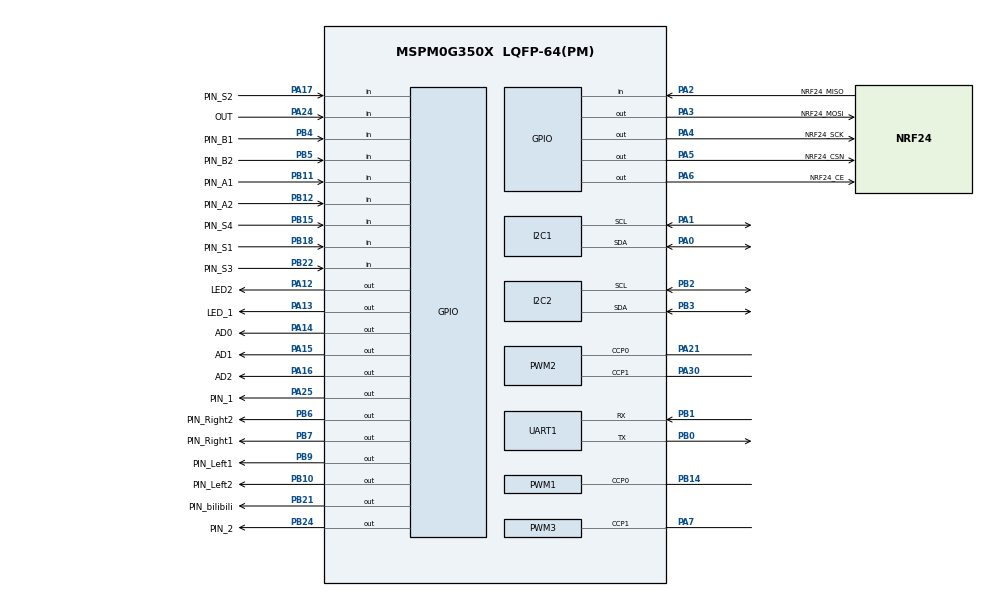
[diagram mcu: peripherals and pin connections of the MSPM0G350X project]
/**
 *
 * @cliArgs --device "MSPM0G350X" --part "Default" --package "LQFP-64(PM)" --product "mspm0_sdk@2.11.00.07"
 * @versions {"tool":"1.28.0+4696"}
 */

/**
 * Import the modules used in this configuration.
 */
const GPIO   = scripting.addModule("/ti/driverlib/GPIO", {}, false);
const GPIO1  = GPIO.addInstance();
const GPIO2  = GPIO.addInstance();
const GPIO3  = GPIO.addInstance();
const GPIO4  = GPIO.addInstance();
const GPIO5  = GPIO.addInstance();
const GPIO6  = GPIO.addInstance();
const GPIO7  = GPIO.addInstance();
const GPIO8  = GPIO.addInstance();
const I2C    = scripting.addModule("/ti/driverlib/I2C", {}, false);
const I2C1   = I2C.addInstance();
const I2C2   = I2C.addInstance();
const PWM    = scripting.addModule("/ti/driverlib/PWM", {}, false);
const PWM1   = PWM.addInstance();
const PWM2   = PWM.addInstance();
const PWM3   = PWM.addInstance();
const SYSCTL = scripting.addModule("/ti/driverlib/SYSCTL");
const TIMER  = scripting.addModule("/ti/driverlib/TIMER", {}, false);
const TIMER1 = TIMER.addInstance();
const TIMER2 = TIMER.addInstance();
const UART   = scripting.addModule("/ti/driverlib/UART", {}, false);
const UART1  = UART.addInstance();

/**
 * Write custom configuration values to the imported modules.
 */
GPIO1.$name                              = "GPIO_Key";
GPIO1.associatedPins.create(4);
GPIO1.associatedPins[0].$name            = "PIN_S1";
GPIO1.associatedPins[0].direction        = "INPUT";
GPIO1.associatedPins[0].internalResistor = "PULL_UP";
GPIO1.associatedPins[0].pin.$assign      = "PB18";
GPIO1.associatedPins[1].$name            = "PIN_S2";
GPIO1.associatedPins[1].direction        = "INPUT";
GPIO1.associatedPins[1].internalResistor = "PULL_UP";
GPIO1.associatedPins[1].pin.$assign      = "PA17";
GPIO1.associatedPins[2].$name            = "PIN_S3";
GPIO1.associatedPins[2].direction        = "INPUT";
GPIO1.associatedPins[2].internalResistor = "PULL_UP";
GPIO1.associatedPins[2].pin.$assign      = "PB22";
GPIO1.associatedPins[3].$name            = "PIN_S4";
GPIO1.associatedPins[3].internalResistor = "PULL_UP";
GPIO1.associatedPins[3].direction        = "INPUT";
GPIO1.associatedPins[3].pin.$assign      = "PB15";

const Board = scripting.addModule("/ti/driverlib/Board", {}, false);

GPIO2.$name                         = "GPIO_Motor";
GPIO2.associatedPins.create(4);
GPIO2.associatedPins[0].$name       = "PIN_Left1";
GPIO2.associatedPins[0].pin.$assign = "PB9";
GPIO2.associatedPins[1].$name       = "PIN_Left2";
GPIO2.associatedPins[1].pin.$assign = "PB10";
GPIO2.associatedPins[2].$name       = "PIN_Right1";
GPIO2.associatedPins[2].pin.$assign = "PB7";
GPIO2.associatedPins[3].$name       = "PIN_Right2";
GPIO2.associatedPins[3].pin.$assign = "PB6";

GPIO3.$name                               = "GPIO_ENCODER";
GPIO3.associatedPins.create(4);
GPIO3.associatedPins[0].direction         = "INPUT";
GPIO3.associatedPins[0].interruptEn       = true;
GPIO3.associatedPins[0].$name             = "PIN_A1";
GPIO3.associatedPins[0].interruptPriority = "0";
GPIO3.associatedPins[0].polarity          = "RISE";
GPIO3.associatedPins[0].pin.$assign       = "PB11";
GPIO3.associatedPins[1].direction         = "INPUT";
GPIO3.associatedPins[1].$name             = "PIN_B1";
GPIO3.associatedPins[1].polarity          = "RISE";
GPIO3.associatedPins[1].interruptEn       = true;
GPIO3.associatedPins[1].interruptPriority = "0";
GPIO3.associatedPins[1].pin.$assign       = "PB4";
GPIO3.associatedPins[2].direction         = "INPUT";
GPIO3.associatedPins[2].interruptEn       = true;
GPIO3.associatedPins[2].$name             = "PIN_A2";
GPIO3.associatedPins[2].interruptPriority = "0";
GPIO3.associatedPins[2].polarity          = "RISE";
GPIO3.associatedPins[2].pin.$assign       = "PB12";
GPIO3.associatedPins[3].direction         = "INPUT";
GPIO3.associatedPins[3].$name             = "PIN_B2";
GPIO3.associatedPins[3].interruptEn       = true;
GPIO3.associatedPins[3].polarity          = "RISE";
GPIO3.associatedPins[3].interruptPriority = "0";
GPIO3.associatedPins[3].pin.$assign       = "PB5";

GPIO4.$name                              = "GPIO_Follow";
GPIO4.associatedPins.create(4);
GPIO4.associatedPins[0].direction        = "INPUT";
GPIO4.associatedPins[0].internalResistor = "PULL_DOWN";
GPIO4.associatedPins[0].$name            = "OUT";
GPIO4.associatedPins[0].pin.$assign      = "PA24";
GPIO4.associatedPins[1].internalResistor = "PULL_DOWN";
GPIO4.associatedPins[1].$name            = "AD0";
GPIO4.associatedPins[1].pin.$assign      = "PA14";
GPIO4.associatedPins[2].internalResistor = "PULL_DOWN";
GPIO4.associatedPins[2].$name            = "AD1";
GPIO4.associatedPins[2].pin.$assign      = "PA15";
GPIO4.associatedPins[3].internalResistor = "PULL_DOWN";
GPIO4.associatedPins[3].$name            = "AD2";
GPIO4.associatedPins[3].pin.$assign      = "PA16";

GPIO5.$name                          = "GPIO_Buzzer";
GPIO5.associatedPins[0].$name        = "PIN_bilibili";
GPIO5.associatedPins[0].initialValue = "SET";
GPIO5.associatedPins[0].pin.$assign  = "PB21";

GPIO6.$name                         = "GPIO_LED";
GPIO6.associatedPins.create(2);
GPIO6.associatedPins[0].$name       = "LED_1";
GPIO6.associatedPins[0].pin.$assign = "PA13";
GPIO6.associatedPins[1].$name       = "LED2";
GPIO6.associatedPins[1].pin.$assign = "PA12";

GPIO7.$name                          = "GPIO_Magnet";
GPIO7.associatedPins.create(3);
GPIO7.associatedPins[0].$name        = "PIN_0";
GPIO7.associatedPins[0].initialValue = "SET";
GPIO7.associatedPins[1].$name        = "PIN_1";
GPIO7.associatedPins[1].initialValue = "SET";
GPIO7.associatedPins[1].pin.$assign  = "PA25";
GPIO7.associatedPins[2].$name        = "PIN_2";
GPIO7.associatedPins[2].initialValue = "SET";
GPIO7.associatedPins[2].pin.$assign  = "PB24";

GPIO8.$name                          = "GPIO_NRF";
GPIO8.associatedPins.create(5);
GPIO8.associatedPins[0].$name        = "NRF24_CE";
GPIO8.associatedPins[0].assignedPort = "PORTA";
GPIO8.associatedPins[0].assignedPin  = "6";
GPIO8.associatedPins[0].pin.$assign  = "PA6";
GPIO8.associatedPins[1].$name        = "NRF24_CSN";
GPIO8.associatedPins[1].initialValue = "SET";
GPIO8.associatedPins[1].assignedPort = "PORTA";
GPIO8.associatedPins[1].assignedPin  = "5";
GPIO8.associatedPins[1].pin.$assign  = "PA5";
GPIO8.associatedPins[2].$name        = "NRF24_SCK";
GPIO8.associatedPins[2].pin.$assign  = "PA4";
GPIO8.associatedPins[3].$name        = "NRF24_MOSI";
GPIO8.associatedPins[3].pin.$assign  = "PA3";
GPIO8.associatedPins[4].$name        = "NRF24_MISO";
GPIO8.associatedPins[4].direction    = "INPUT";
GPIO8.associatedPins[4].pin.$assign  = "PA2";

I2C1.$name                             = "I2C_OLED";
I2C1.basicEnableController             = true;
I2C1.intController                     = ["ARBITRATION_LOST","NACK","RXFIFO_TRIGGER","RX_DONE","TX_DONE"];
I2C1.basicControllerStandardBusSpeed   = "Fast";
I2C1.peripheral.sdaPin.$assign         = "PA0";
I2C1.peripheral.sclPin.$assign         = "PA1";
I2C1.sdaPinConfig.$name                = "ti_driverlib_gpio_GPIOPinGeneric0";
I2C1.sdaPinConfig.hideOutputInversion  = scripting.forceWrite(false);
I2C1.sdaPinConfig.onlyInternalResistor = scripting.forceWrite(false);
I2C1.sdaPinConfig.passedPeripheralType = scripting.forceWrite("Digital");
I2C1.sclPinConfig.$name                = "ti_driverlib_gpio_GPIOPinGeneric1";
I2C1.sclPinConfig.hideOutputInversion  = scripting.forceWrite(false);
I2C1.sclPinConfig.onlyInternalResistor = scripting.forceWrite(false);
I2C1.sclPinConfig.passedPeripheralType = scripting.forceWrite("Digital");

I2C2.$name                             = "I2C_MPU6050";
I2C2.basicEnableController             = true;
I2C2.intController                     = ["ARBITRATION_LOST","NACK","RXFIFO_TRIGGER","RX_DONE","TX_DONE"];
I2C2.peripheral.sdaPin.$assign         = "PB3";
I2C2.peripheral.sclPin.$assign         = "PB2";
I2C2.sdaPinConfig.$name                = "ti_driverlib_gpio_GPIOPinGeneric2";
I2C2.sdaPinConfig.hideOutputInversion  = scripting.forceWrite(false);
I2C2.sdaPinConfig.onlyInternalResistor = scripting.forceWrite(false);
I2C2.sdaPinConfig.passedPeripheralType = scripting.forceWrite("Digital");
I2C2.sclPinConfig.$name                = "ti_driverlib_gpio_GPIOPinGeneric3";
I2C2.sclPinConfig.hideOutputInversion  = scripting.forceWrite(false);
I2C2.sclPinConfig.onlyInternalResistor = scripting.forceWrite(false);
I2C2.sclPinConfig.passedPeripheralType = scripting.forceWrite("Digital");

PWM1.$name                              = "PWM_Car";
PWM1.pwmMode                            = "EDGE_ALIGN_UP";
PWM1.timerCount                         = 3200;
PWM1.timerStartTimer                    = true;
PWM1.ccIndex                            = [0];
PWM1.PWM_CHANNEL_0.$name                = "ti_driverlib_pwm_PWMTimerCC0";
PWM1.ccp0PinConfig.$name                = "ti_driverlib_gpio_GPIOPinGeneric4";
PWM1.ccp0PinConfig.direction            = scripting.forceWrite("OUTPUT");
PWM1.ccp0PinConfig.hideOutputInversion  = scripting.forceWrite(false);
PWM1.ccp0PinConfig.onlyInternalResistor = scripting.forceWrite(false);
PWM1.ccp0PinConfig.passedPeripheralType = scripting.forceWrite("Digital");
PWM1.peripheral.$assign                 = "TIMA0";
PWM1.peripheral.ccp0Pin.$assign         = "PB14";

PWM2.$name                              = "PWM_Servo";
PWM2.enableShadowLoad                   = true;
PWM2.dutyArgs                           = "[2.5,2.5,0,0]";
PWM2.clockDivider                       = 8;
PWM2.clockPrescale                      = 80;
PWM2.peripheral.$assign                 = "TIMG6";
PWM2.peripheral.ccp0Pin.$assign         = "PA21";
PWM2.peripheral.ccp1Pin.$assign         = "PA30";
PWM2.PWM_CHANNEL_0.$name                = "ti_driverlib_pwm_PWMTimerServo0";
PWM2.PWM_CHANNEL_1.$name                = "ti_driverlib_pwm_PWMTimerServo1";
PWM2.ccp0PinConfig.direction            = scripting.forceWrite("OUTPUT");
PWM2.ccp0PinConfig.hideOutputInversion  = scripting.forceWrite(false);
PWM2.ccp0PinConfig.onlyInternalResistor = scripting.forceWrite(false);
PWM2.ccp0PinConfig.passedPeripheralType = scripting.forceWrite("Digital");
PWM2.ccp0PinConfig.$name                = "ti_driverlib_gpio_GPIOPinGeneric12";
PWM2.ccp1PinConfig.direction            = scripting.forceWrite("OUTPUT");
PWM2.ccp1PinConfig.hideOutputInversion  = scripting.forceWrite(false);
PWM2.ccp1PinConfig.onlyInternalResistor = scripting.forceWrite(false);
PWM2.ccp1PinConfig.passedPeripheralType = scripting.forceWrite("Digital");
PWM2.ccp1PinConfig.$name                = "ti_driverlib_gpio_GPIOPinGeneric13";

PWM3.$name                              = "PWM_Car_Left";
PWM3.timerCount                         = 3200;
PWM3.timerStartTimer                    = true;
PWM3.ccIndex                            = [1];
PWM3.ccp1PinConfig.direction            = scripting.forceWrite("OUTPUT");
PWM3.ccp1PinConfig.hideOutputInversion  = scripting.forceWrite(false);
PWM3.ccp1PinConfig.onlyInternalResistor = scripting.forceWrite(false);
PWM3.ccp1PinConfig.passedPeripheralType = scripting.forceWrite("Digital");
PWM3.ccp1PinConfig.$name                = "ti_driverlib_gpio_GPIOPinGeneric8";
PWM3.peripheral.$assign                 = "TIMG7";
PWM3.peripheral.ccp1Pin.$assign         = "PA7";
PWM3.PWM_CHANNEL_1.$name                = "ti_driverlib_pwm_PWMTimerCC1";

SYSCTL.forceDefaultClkConfig = true;

TIMER1.$name              = "TIMER_10ms";
TIMER1.timerClkPrescale   = 256;
TIMER1.interrupts         = ["ZERO"];
TIMER1.timerMode          = "PERIODIC";
TIMER1.timerPeriod        = "10ms";
TIMER1.peripheral.$assign = "TIMG0";

TIMER2.$name              = "TIMER_TICK";
TIMER2.timerClkDiv        = 8;
TIMER2.timerClkPrescale   = 10;
TIMER2.timerPeriod        = "20 ms";
TIMER2.interrupts         = ["ZERO"];
TIMER2.interruptPriority  = "3";
TIMER2.peripheral.$assign = "TIMA1";

UART1.uartClkDiv                       = "8";
UART1.rxFifoThreshold                  = "DL_UART_RX_FIFO_LEVEL_ONE_ENTRY";
UART1.enableDMARX                      = false;
UART1.enableDMATX                      = false;
UART1.$name                            = "UART_JY61P";
UART1.enabledInterrupts                = ["RX"];
UART1.peripheral.$assign               = "UART0";
UART1.peripheral.rxPin.$assign         = "PB1";
UART1.peripheral.txPin.$assign         = "PB0";
UART1.txPinConfig.direction            = scripting.forceWrite("OUTPUT");
UART1.txPinConfig.hideOutputInversion  = scripting.forceWrite(false);
UART1.txPinConfig.onlyInternalResistor = scripting.forceWrite(false);
UART1.txPinConfig.passedPeripheralType = scripting.forceWrite("Digital");
UART1.txPinConfig.$name                = "ti_driverlib_gpio_GPIOPinGeneric6";
UART1.rxPinConfig.hideOutputInversion  = scripting.forceWrite(false);
UART1.rxPinConfig.onlyInternalResistor = scripting.forceWrite(false);
UART1.rxPinConfig.passedPeripheralType = scripting.forceWrite("Digital");
UART1.rxPinConfig.$name                = "ti_driverlib_gpio_GPIOPinGeneric7";

/**
 * Pinmux solution for unlocked pins/peripherals. This ensures that minor changes to the automatic solver in a future
 * version of the tool will not impact the pinmux you originally saw.  These lines can be completely deleted in order to
 * re-solve from scratch.
 */
Board.peripheral.$suggestSolution            = "DEBUGSS";
Board.peripheral.swclkPin.$suggestSolution   = "PA20";
Board.peripheral.swdioPin.$suggestSolution   = "PA19";
GPIO7.associatedPins[0].pin.$suggestSolution = "PB13";
I2C1.peripheral.$suggestSolution             = "I2C0";
I2C2.peripheral.$suggestSolution             = "I2C1";
SYSCTL.peripheral.$suggestSolution           = "SYSCTL";
